# LPC5410x register map
File version: 0.4
CPU: CM4 r0p0, little endian, no MPU, no FPU, 0x3 interrupt priority bits, 0x0 interrupts
Registers are 32-bit, read-write, reset 0x0 unless marked. A register's access mark holds for its fields unless they carry their own. Offsets are from the block's base; [hi:lo] are bit positions; {n}, {i} and the like mark numbered series.

## ASYNCSYSCON — Asynchronous system configuration
Base 0x40080000
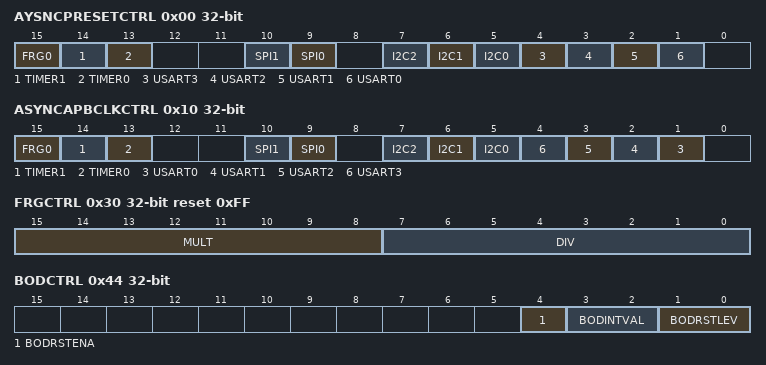
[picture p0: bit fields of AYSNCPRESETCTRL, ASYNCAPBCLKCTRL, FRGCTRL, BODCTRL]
0x00 AYSNCPRESETCTRL — Async peripheral reset control
  [15] FRG0 — FRG reset control. 0 = Clear reset to this function. 1 = Assert reset to this function.
  [14] TIMER1 — Timer 1 reset control. 0 = Clear reset to this function. 1 = Assert reset to this function.
  [13] TIMER0 — Timer 0 reset control. 0 = Clear reset to this function. 1 = Assert reset to this function.
  [10] SPI1 — SPI1 reset control. 0 = Clear reset to this function. 1 = Assert reset to this function.
  [9] SPI0 — SPI0 reset control. 0 = Clear reset to this function. 1 = Assert reset to this function.
  [7] I2C2 — I2C2 reset control. 0 = Clear reset to this function. 1 = Assert reset to this function.
  [6] I2C1 — I2C1 reset control. 0 = Clear reset to this function. 1 = Assert reset to this function.
  [5] I2C0 — I2C0 reset control. 0 = Clear reset to this function. 1 = Assert reset to this function.
  [4] USART3 — USART3 reset control. 0 = Clear reset to this function. 1 = Assert reset to this function.
  [3] USART2 — USART2 reset control.0 = Clear reset to this function. 1 = Assert reset to this function.
  [2] USART1 — USART1 reset control. 0 = Clear reset to this function. 1 = Assert reset to this function.
  [1] USART0 — USART0 reset control. 0 = Clear reset to this function. 1 = Assert reset to this function.
0x04 AYSNCPRESETCTRLSET wo reset not defined — Set bits in AYSNCPRESETCTRL
  [31:0] ARST_SET — Writing ones to this register sets the corresponding bit or bits in the AYSNCPRESETCTRL register, if they are implemented. Bits that do not correspond to defined bits in AYSNCPRESETCTRL are reserved and only zeroes should be written to them.
0x08 AYSNCPRESETCTRLCLR wo reset not defined — Clear bits in AYSNCPRESETCTRL
  [31:0] ARST_CLR — Writing ones to this register clears the corresponding bit or bits in the AYSNCPRESETCTRL register, if they are implemented. Bits that do not correspond to defined bits in AYSNCPRESETCTRL are reserved and only zeroes should be written to them.
0x10 ASYNCAPBCLKCTRL — Async peripheral clock control
  [15] FRG0 — Controls the clock for the Fractional Rate Generator used with the USARTs. 0 = Disable; 1 = Enable.
  [14] TIMER1 — Controls the clock for TIMER1. 0 = Disable; 1 = Enable.
  [13] TIMER0 — Controls the clock for TIMER0. 0 = Disable; 1 = Enable.
  [10] SPI1 — Controls the clock for SPI1. 0 = Disable; 1 = Enable.
  [9] SPI0 — Controls the clock for SPI0. 0 = Disable; 1 = Enable.
  [7] I2C2 — Controls the clock for I2C2. 0 = Disable; 1 = Enable.
  [6] I2C1 — Controls the clock for I2C1. 0 = Disable; 1 = Enable.
  [5] I2C0 — Controls the clock for I2C0. 0 = Disable; 1 = Enable.
  [n+1] USART{n} (n=0..3) — Controls the clock for USART{n}. 0 = Disable; 1 = Enable.
0x14 ASYNCAPBCLKCTRLSET wo reset not defined — Set bits in ASYNCAPBCLKCTRL
  [31:0] ACLK_SET — Writing ones to this register sets the corresponding bit or bits in the ASYNCAPBCLKCTRL register, if they are implemented. Bits that do not correspond to defined bits in AYSNCPRESETCTRL are reserved and only zeroes should be written to them.
0x18 ASYNCAPBCLKCTRLCLR wo reset not defined — Clear bits in ASYNCAPBCLKCTRL
  [31:0] ACLK_CLR — Writing ones to this register clears the corresponding bit or bits in the ASYNCAPBCLKCTRL register, if they are implemented. Bits that do not correspond to defined bits in ASYNCAPBCLKCTRL are reserved and only zeroes should be written to them.
0x20 ASYNCAPBCLKSELA — Async APB clock source select A
  [1:0] SEL — Clock source for asynchronous clock source selector A
    0=IRC_OSCILLATOR; 1=WATCHDOG_OSCILLATOR
0x24 ASYNCAPBCLKSELB — Async APB clock source select B
  [1:0] SEL — Clock source for asynchronous clock source selector B.
    0=MAIN_CLOCK; 1=CLKIN; 2=SYSTEM_PLL_OUTPUT; 3=ASYNCAPBCLKSELA (ASYNCAPBCLKSELA. Clock selected by the ASYNCAPBCLKSELA register.)
0x28 ASYNCCLKDIV reset 0x1 — Async APB clock divider
  [7:0] DIV — Asynchronous APB clock divider value. 0: Clock disabled. 1: Divide by 1. to 255: Divide by 255.
0x30 FRGCTRL reset 0xFF — USART fractional rate generator control
  [15:8] MULT — Numerator of the fractional divider. MULT is equal to the programmed value.
  [7:0] DIV — Denominator of the fractional divider. DIV is equal to the programmed value +1. Always set to 0xFF to use with the fractional baud rate generator.
0x44 BODCTRL — Brown-Out Detect control
  [4] BODRSTENA — BOD reset enable
    0=DISABLE_RESET_FUNCTI (Disable reset function.); 1=ENABLE_RESET_FUNCTIO (Enable reset function.)
  [3:2] BODINTVAL — BOD interrupt level
    0=LEVEL_0_2 (Level 0: 2.05 V); 1=LEVEL_1_2 (Level 1: 2.45 V); 2=LEVEL_2_2 (Level 2: 2.75 V); 3=LEVEL_3_3 (Level 3: 3.05 V)
  [1:0] BODRSTLEV — BOD reset level
    0=LEVEL_0_1 (Level 0: 1.5 V); 1=LEVEL_1_1 (Level 1: 1.85 V); 2=LEVEL_2_2 (Level 2: 2.0 V); 3=LEVEL_3_2 (Level 3: 2.3 V)
